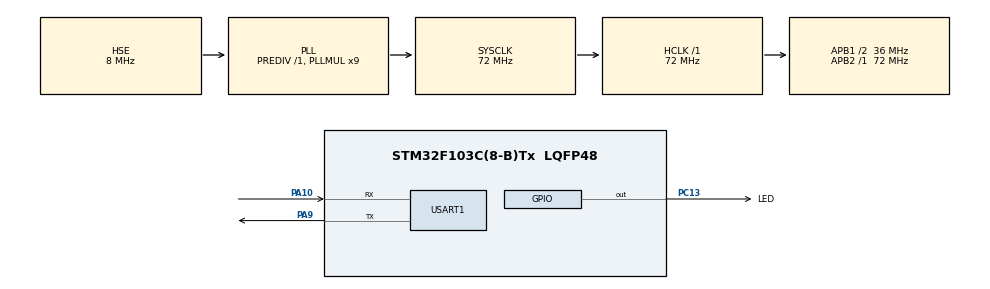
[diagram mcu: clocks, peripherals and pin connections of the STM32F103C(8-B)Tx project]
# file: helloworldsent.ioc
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Mcu.Family=STM32F1
Mcu.Name=STM32F103C(8-B)Tx
Mcu.Package=LQFP48
NVIC.PriorityGroup=NVIC_PRIORITYGROUP_4
NVIC.USART1_IRQn=true\:1\:0\:true\:false\:true\:true\:true\:true
PA10.Mode=Asynchronous
PA10.Signal=USART1_RX
PA13.Mode=Serial_Wire
PA13.Signal=SYS_JTMS-SWDIO
PA14.Mode=Serial_Wire
PA14.Signal=SYS_JTCK-SWCLK
PA9.Mode=Asynchronous
PA9.Signal=USART1_TX
PC13-TAMPER-RTC.GPIO_Label=LED
PC13-TAMPER-RTC.PinState=GPIO_PIN_SET
PC13-TAMPER-RTC.Signal=GPIO_Output
PD0-OSC_IN.Mode=HSE-External-Oscillator
PD0-OSC_IN.Signal=RCC_OSC_IN
PD1-OSC_OUT.Mode=HSE-External-Oscillator
PD1-OSC_OUT.Signal=RCC_OSC_OUT
ProjectManager.HeapSize=0x200
ProjectManager.StackSize=0x400
ProjectManager.TargetToolchain=CMake
RCC.AHBFreq_Value=72000000
RCC.APB1CLKDivider=RCC_HCLK_DIV2
RCC.APB1Freq_Value=36000000
RCC.APB1TimFreq_Value=72000000
RCC.APB2Freq_Value=72000000
RCC.APB2TimFreq_Value=72000000
RCC.HCLKFreq_Value=72000000
RCC.PLLMUL=RCC_PLL_MUL9
RCC.PLLSourceVirtual=RCC_PLLSOURCE_HSE
RCC.SYSCLKFreq_VALUE=72000000
RCC.SYSCLKSource=RCC_SYSCLKSOURCE_PLLCLK
RCC.USBFreq_Value=72000000
USART1.VirtualMode=VM_ASYNC
board=custom

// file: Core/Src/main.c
/* USER CODE BEGIN Header */
/**
  ******************************************************************************
  * @file           : main.c
  * @brief          : Main program body
  ******************************************************************************
  * @attention
  *
  * Copyright (c) 2026 STMicroelectronics.
  * All rights reserved.
  *
  * This software is licensed under terms that can be found in the LICENSE file
  * in the root directory of this software component.
  * If no LICENSE file comes with this software, it is provided AS-IS.
  *
  ******************************************************************************
  */
/* USER CODE END Header */
#include "main.h"

UART_HandleTypeDef huart1;

/* USER CODE BEGIN PV */
static const uint8_t HELLO_MSG[] = "Hello World!\r\n";
static const uint8_t MENU_MSG[] =
  "\r\n=== LED Blink Control ===\r\n"
  "1:P1000  2:P500  3:P250  4:P100  5:P50\r\n"
  "0:stop   +:slower   -:faster\r\n"
  "========================\r\n";

volatile uint32_t led_interval_ms = 500U;
volatile uint8_t  led_running     = 1U;
uint32_t          last_toggle_tick = 0U;

uint8_t          rx_byte   = 0U;
volatile uint8_t rx_cmd    = 0U;
volatile uint8_t rx_ready  = 0U;
/* USER CODE END PV */

void SystemClock_Config(void);
static void MX_GPIO_Init(void);
static void MX_USART1_UART_Init(void);

/* USER CODE BEGIN 0 */
static void uart_send(const char *s)
{
  uint16_t len = 0U;

  while (s[len] != '\0')
  {
    len++;
  }
  HAL_UART_Transmit(&huart1, (uint8_t *)s, len, 100U);
}

static void uart_report(uint32_t ms)
{
  char     buf[24];
  char     num[10];
  uint32_t i = 0U;
  uint32_t n = 0U;

  buf[i++] = 'O';
  buf[i++] = 'K';
  buf[i++] = ' ';

  if (ms == 0U)
  {
    num[n++] = '0';
  }
  while (ms > 0U)
  {
    num[n++] = (char)('0' + (ms % 10U));
    ms /= 10U;
  }
  while (n > 0U)
  {
    buf[i++] = num[--n];
  }

  buf[i++] = ' ';
  buf[i++] = 'm';
  buf[i++] = 's';
  buf[i++] = '\r';
  buf[i++] = '\n';

  HAL_UART_Transmit(&huart1, (uint8_t *)buf, (uint16_t)i, 100U);
}
/* USER CODE END 0 */

int main(void)
{

  /* MCU Configuration--------------------------------------------------------*/

  /* Reset of all peripherals, Initializes the Flash interface and the Systick. */
  HAL_Init();

  /* Configure the system clock */
  SystemClock_Config();

  /* Initialize all configured peripherals */
  MX_GPIO_Init();
  MX_USART1_UART_Init();
  /* USER CODE BEGIN 2 */
  uart_send((const char *)HELLO_MSG);
  uart_send((const char *)MENU_MSG);

  led_running        = 1U;
  led_interval_ms    = 500U;
  last_toggle_tick   = HAL_GetTick();

  HAL_UART_Receive_IT(&huart1, &rx_byte, 1U);
  /* USER CODE END 2 */

  /* Infinite loop */
  while (1)
  {

    /* USER CODE BEGIN 3 */
    if (rx_ready != 0U)
    {
      uint8_t cmd = rx_cmd;
      rx_ready = 0U;

      switch (cmd)
      {
        case '0':
          led_running = 0U;
          HAL_GPIO_WritePin(LED_GPIO_Port, LED_Pin, GPIO_PIN_SET);
          uart_send("STOP\r\n");
          break;

        case '1':
          led_interval_ms = 1000U;
          led_running     = 1U;
          uart_report(led_interval_ms);
          break;

        case '2':
          led_interval_ms = 500U;
          led_running     = 1U;
          uart_report(led_interval_ms);
          break;

        case '3':
          led_interval_ms = 250U;
          led_running     = 1U;
          uart_report(led_interval_ms);
          break;

        case '4':
          led_interval_ms = 100U;
          led_running     = 1U;
          uart_report(led_interval_ms);
          break;

        case '5':
          led_interval_ms = 50U;
          led_running     = 1U;
          uart_report(led_interval_ms);
          break;

        case '+':
          if (led_interval_ms < 2000U)
          {
            led_interval_ms += 100U;
          }
          led_running = 1U;
          uart_report(led_interval_ms);
          break;

        case '-':
          if (led_interval_ms > 100U)
          {
            led_interval_ms -= 100U;
          }
          led_running = 1U;
          uart_report(led_interval_ms);
          break;

        case '\r':
        case '\n':
          break;

        default:
          uart_send("? use 0-5 or + -\r\n");
          break;
      }
    }

    if ((led_running != 0U) &&
        ((HAL_GetTick() - last_toggle_tick) >= led_interval_ms))
    {
      last_toggle_tick = HAL_GetTick();
      HAL_GPIO_TogglePin(LED_GPIO_Port, LED_Pin);
    }
  }
  /* USER CODE END 3 */
}

void SystemClock_Config(void)
{
  RCC_OscInitTypeDef RCC_OscInitStruct = {0};
  RCC_ClkInitTypeDef RCC_ClkInitStruct = {0};

  /** Initializes the RCC Oscillators according to the specified parameters
  * in the RCC_OscInitTypeDef structure.
  */
  RCC_OscInitStruct.OscillatorType = RCC_OSCILLATORTYPE_HSE;
  RCC_OscInitStruct.HSEState = RCC_HSE_ON;
  RCC_OscInitStruct.HSEPredivValue = RCC_HSE_PREDIV_DIV1;
  RCC_OscInitStruct.HSIState = RCC_HSI_ON;
  RCC_OscInitStruct.PLL.PLLState = RCC_PLL_ON;
  RCC_OscInitStruct.PLL.PLLSource = RCC_PLLSOURCE_HSE;
  RCC_OscInitStruct.PLL.PLLMUL = RCC_PLL_MUL9;
  if (HAL_RCC_OscConfig(&RCC_OscInitStruct) != HAL_OK)
  {
    Error_Handler();
  }

  /** Initializes the CPU, AHB and APB buses clocks
  */
  RCC_ClkInitStruct.ClockType = RCC_CLOCKTYPE_HCLK|RCC_CLOCKTYPE_SYSCLK
                              |RCC_CLOCKTYPE_PCLK1|RCC_CLOCKTYPE_PCLK2;
  RCC_ClkInitStruct.SYSCLKSource = RCC_SYSCLKSOURCE_PLLCLK;
  RCC_ClkInitStruct.AHBCLKDivider = RCC_SYSCLK_DIV1;
  RCC_ClkInitStruct.APB1CLKDivider = RCC_HCLK_DIV2;
  RCC_ClkInitStruct.APB2CLKDivider = RCC_HCLK_DIV1;

  if (HAL_RCC_ClockConfig(&RCC_ClkInitStruct, FLASH_LATENCY_2) != HAL_OK)
  {
    Error_Handler();
  }
}

static void MX_USART1_UART_Init(void)
{

  huart1.Instance = USART1;
  huart1.Init.BaudRate = 115200;
  huart1.Init.WordLength = UART_WORDLENGTH_8B;
  huart1.Init.StopBits = UART_STOPBITS_1;
  huart1.Init.Parity = UART_PARITY_NONE;
  huart1.Init.Mode = UART_MODE_TX_RX;
  huart1.Init.HwFlowCtl = UART_HWCONTROL_NONE;
  huart1.Init.OverSampling = UART_OVERSAMPLING_16;
  if (HAL_UART_Init(&huart1) != HAL_OK)
  {
    Error_Handler();
  }

}

static void MX_GPIO_Init(void)
{
  GPIO_InitTypeDef GPIO_InitStruct = {0};

  /* GPIO Ports Clock Enable */
  __HAL_RCC_GPIOC_CLK_ENABLE();
  __HAL_RCC_GPIOD_CLK_ENABLE();
  __HAL_RCC_GPIOA_CLK_ENABLE();

  /*Configure GPIO pin Output Level */
  HAL_GPIO_WritePin(LED_GPIO_Port, LED_Pin, GPIO_PIN_SET);

  /*Configure GPIO pin : LED_Pin */
  GPIO_InitStruct.Pin = LED_Pin;
  GPIO_InitStruct.Mode = GPIO_MODE_OUTPUT_PP;
  GPIO_InitStruct.Pull = GPIO_NOPULL;
  GPIO_InitStruct.Speed = GPIO_SPEED_FREQ_LOW;
  HAL_GPIO_Init(LED_GPIO_Port, &GPIO_InitStruct);

}

/* USER CODE BEGIN 4 */
void HAL_UART_RxCpltCallback(UART_HandleTypeDef *huart)
{
  if (huart->Instance == USART1)
  {
    rx_cmd   = rx_byte;
    rx_ready = 1U;

    /* 重新挂上接收，否则只能收到一个字节 */
    HAL_UART_Receive_IT(&huart1, &rx_byte, 1U);
  }
}
/* USER CODE END 4 */

void Error_Handler(void)
{
  __disable_irq();
  while (1)
  {
  }
}
